AUTOSAR XML (schema 00046)
package /ComponentTypes
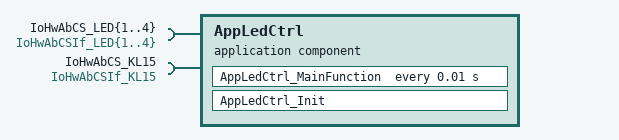
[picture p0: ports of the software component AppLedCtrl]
  application sw component type AppLedCtrl
    5 x require port:
      IoHwAbCS_LED{1..4}: required-com-specs=[IoHwAbOp_LED{1..4}_Read, IoHwAbOp_LED{1..4}_Write], required-interface=IoHwAbCSIf_LED{1..4}
      IoHwAbCS_KL15: client-com-spec=IoHwAbOp_KL15_Read, required-interface=IoHwAbCSIf_KL15
    behavior AppLedCtrl_InternalBehavior
      init event AppLedCtrl_InitEvent: start-on-event=AppLedCtrl_Init
      timing event TMT_Runnable: start-on-event=AppLedCtrl_MainFunction, period=0.01
      runnable AppLedCtrl_Init
      runnable AppLedCtrl_MainFunction
        9 x sync call:
          SC_IoHwAbCS_KL15_IoHwAbOp_KL15_Read: operation=IoHwAbCS_KL15.IoHwAbOp_KL15_Read
          SC_IoHwAbCS_LED1_IoHwAbOp_LED1_Read: operation=IoHwAbCS_LED1.IoHwAbOp_LED1_Read
          SC_IoHwAbCS_LED1_IoHwAbOp_LED1_Write: operation=IoHwAbCS_LED1.IoHwAbOp_LED1_Write
          SC_IoHwAbCS_LED2_IoHwAbOp_LED2_Read: operation=IoHwAbCS_LED2.IoHwAbOp_LED2_Read
          SC_IoHwAbCS_LED2_IoHwAbOp_LED2_Write: operation=IoHwAbCS_LED2.IoHwAbOp_LED2_Write
          SC_IoHwAbCS_LED3_IoHwAbOp_LED3_Read: operation=IoHwAbCS_LED3.IoHwAbOp_LED3_Read
          SC_IoHwAbCS_LED3_IoHwAbOp_LED3_Write: operation=IoHwAbCS_LED3.IoHwAbOp_LED3_Write
          SC_IoHwAbCS_LED4_IoHwAbOp_LED4_Read: operation=IoHwAbCS_LED4.IoHwAbOp_LED4_Read
          SC_IoHwAbCS_LED4_IoHwAbOp_LED4_Write: operation=IoHwAbCS_LED4.IoHwAbOp_LED4_Write
  swc implementation AppLedCtrl_Implementation: behavior=AppLedCtrl_InternalBehavior
